# MIMXRT1064 register map
Vendor: nxp.com; File version: 1.0
CPU: CM7 r0p1, little endian, MPU, FPU, VTOR, 4 interrupt priority bits
Registers are 32-bit, read-write, reset 0x0 unless marked. A register's access mark holds for its fields unless they carry their own. Offsets are from the block's base; [hi:lo] are bit positions; {n}, {i} and the like mark numbered series; 'fields as' and 'values as' point back to an identical list.

## DCP — DCP register reference index
Base 0x402FC000; register names take the prefix DCP_
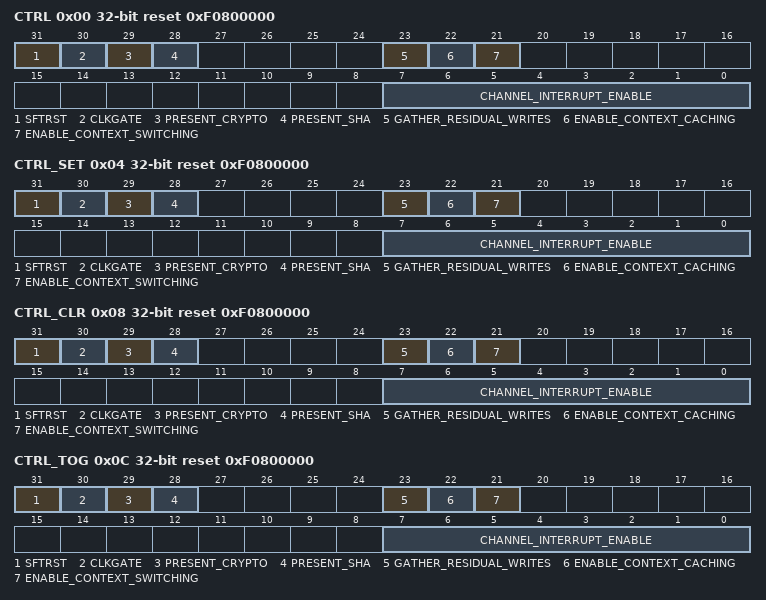
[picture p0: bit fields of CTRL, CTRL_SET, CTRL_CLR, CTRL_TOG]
0x00 CTRL reset 0xF0800000 — DCP control register 0
  [31] SFTRST — Set this bit to zero to enable a normal DCP operation
  [30] CLKGATE — This bit must be set to zero for a normal operation
  [29] PRESENT_CRYPTO ro — Indicates whether the crypto (cipher/hash) functions are present.
    0=Absent; 1=Present
  [28] PRESENT_SHA ro — Indicates whether the SHA1/SHA2 functions are present.
    0=Absent; 1=Present
  [23] GATHER_RESIDUAL_WRITES — The software must set this bit to enable the ragged writes to the unaligned buffers to be gathered between multiple write operations
  [22] ENABLE_CONTEXT_CACHING — The software must set this bit to enable the caching of contexts between the operations
  [21] ENABLE_CONTEXT_SWITCHING — Enable automatic context switching for the channels
  [7:0] CHANNEL_INTERRUPT_ENABLE — Per-channel interrupt enable bit
    1=CH0; 2=CH1; 4=CH2; 8=CH3
0x04 CTRL_SET reset 0xF0800000 — DCP control register 0
  fields as CTRL
0x08 CTRL_CLR reset 0xF0800000 — DCP control register 0
  fields as CTRL
0x0C CTRL_TOG reset 0xF0800000 — DCP control register 0
  fields as CTRL
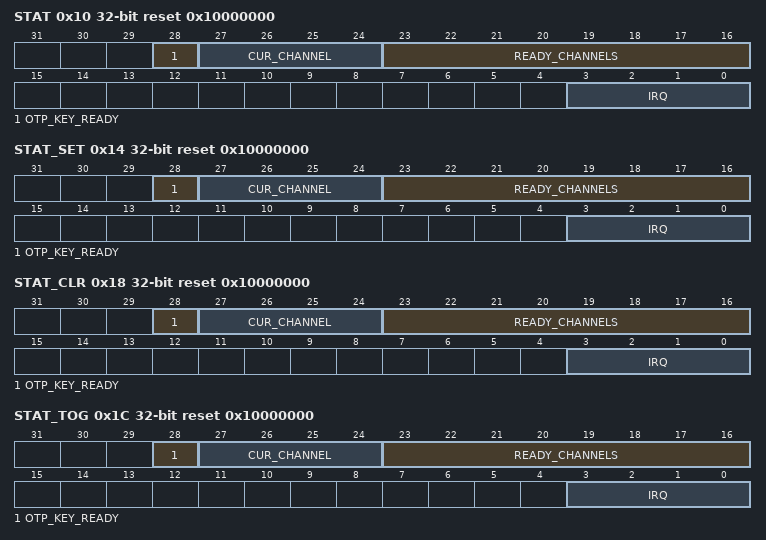
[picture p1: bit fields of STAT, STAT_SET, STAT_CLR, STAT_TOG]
0x10 STAT reset 0x10000000 — DCP status register
  [28] OTP_KEY_READY ro — When set, it indicates that the OTP key is shifted from the fuse block and is ready for use.
  [27:24] CUR_CHANNEL ro — Current (active) channel (encoded)
    0=None; {v}=CH{v-1} (v=1..4)
  [23:16] READY_CHANNELS ro — Indicates which channels are ready to proceed with a transfer (the active channel is also included)
    1=CH0; 2=CH1; 4=CH2; 8=CH3
  [3:0] IRQ — Indicates which channels have pending interrupt requests
0x14 STAT_SET reset 0x10000000 — DCP status register
  fields as STAT
0x18 STAT_CLR reset 0x10000000 — DCP status register
  fields as STAT
0x1C STAT_TOG reset 0x10000000 — DCP status register
  fields as STAT
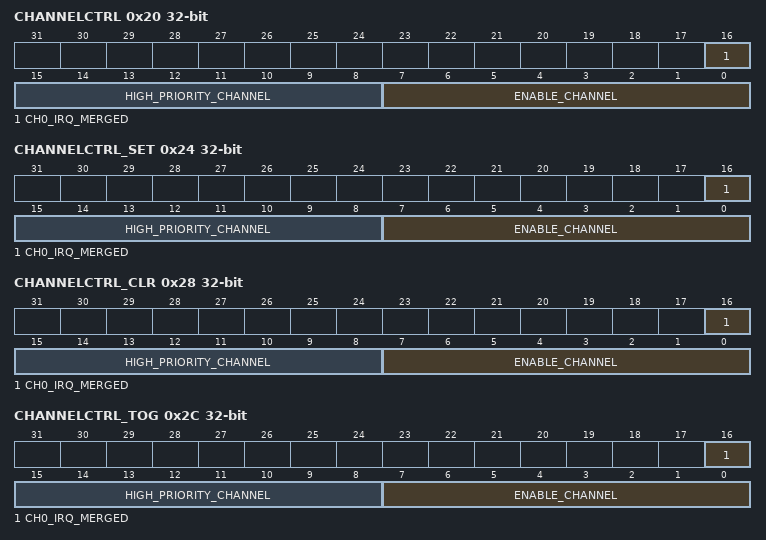
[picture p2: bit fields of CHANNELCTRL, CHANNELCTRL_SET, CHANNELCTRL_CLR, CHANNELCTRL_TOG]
0x20 CHANNELCTRL — DCP channel control register
  [16] CH0_IRQ_MERGED — Indicates that the interrupt for channel 0 must be merged with the other interrupts on the shared dcp_irq interrupt
  [15:8] HIGH_PRIORITY_CHANNEL — Setting a bit in this field causes the corresponding channel to have high-priority arbitration
    1=CH0; 2=CH1; 4=CH2; 8=CH3
  [7:0] ENABLE_CHANNEL — Setting a bit in this field enables the DMA channel associated with it
    1=CH0; 2=CH1; 4=CH2; 8=CH3
0x24 CHANNELCTRL_SET — DCP channel control register
  fields as CHANNELCTRL
0x28 CHANNELCTRL_CLR — DCP channel control register
  fields as CHANNELCTRL
0x2C CHANNELCTRL_TOG — DCP channel control register
  fields as CHANNELCTRL
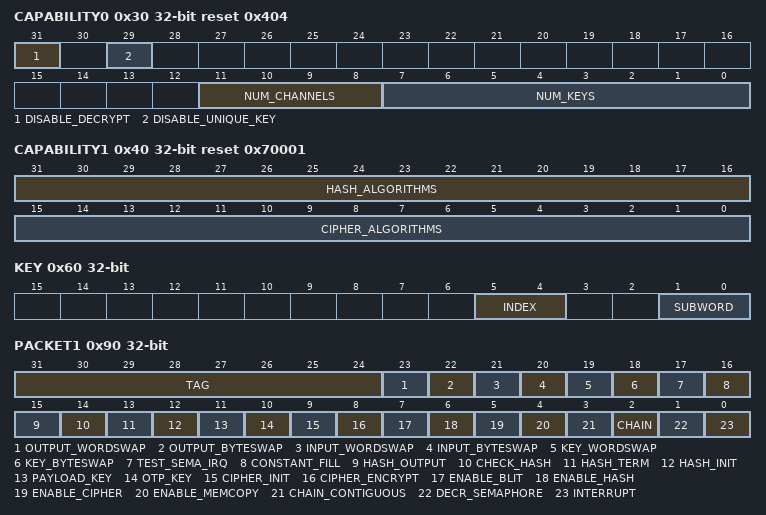
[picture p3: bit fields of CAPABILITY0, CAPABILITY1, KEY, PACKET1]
0x30 CAPABILITY0 reset 0x404 — DCP capability 0 register
  [31] DISABLE_DECRYPT — Write to 1 to disable the decryption
  [29] DISABLE_UNIQUE_KEY — Write to a 1 to disable the per-device unique key
  [11:8] NUM_CHANNELS ro — Encoded value indicating the number of channels implemented in the design
  [7:0] NUM_KEYS ro — Encoded value indicating the number of key-storage locations implemented in the design
0x40 CAPABILITY1 ro reset 0x70001 — DCP capability 1 register
  [31:16] HASH_ALGORITHMS — One-hot field indicating which hashing features are implemented in the hardware
    1=SHA1; 2=CRC32; 4=SHA256
  [15:0] CIPHER_ALGORITHMS — One-hot field indicating which cipher algorithms are available
    1=AES128
0x50 CONTEXT — DCP context buffer pointer
  [31:0] ADDR — Context pointer address
0x60 KEY — DCP key index
  [5:4] INDEX — Key index pointer. The valid indices are 0-[number_keys].
  [1:0] SUBWORD — Key subword pointer
0x70 KEYDATA — DCP key data
  [31:0] DATA — Word 0 data for the key. This is the least-significant word.
0x80 PACKET0 ro — DCP work packet 0 status register
  [31:0] ADDR — Next pointer register
0x90 PACKET1 ro — DCP work packet 1 status register
  [31:24] TAG — Packet Tag
  [23] OUTPUT_WORDSWAP — Reflects whether the DCP engine wordswaps the output data (big-endian data).
  [22] OUTPUT_BYTESWAP — Reflects whether the DCP engine byteswaps the output data (big-endian data).
  [21] INPUT_WORDSWAP — Reflects whether the DCP engine wordswaps the input data (big-endian data).
  [20] INPUT_BYTESWAP — Reflects whether the DCP engine byteswaps the input data (big-endian data).
  [19] KEY_WORDSWAP — Reflects whether the DCP engine swaps the key words (big-endian key).
  [18] KEY_BYTESWAP — Reflects whether the DCP engine swaps the key bytes (big-endian key).
  [17] TEST_SEMA_IRQ — This bit is used to test the channel semaphore transition to 0. FOR TEST USE ONLY!
  [16] CONSTANT_FILL — When this bit is set (MEMCOPY and BLIT modes only), the DCP simply fills the destination buffer with the value found in the source address field
  [15] HASH_OUTPUT — When the hashing is enabled, this bit controls whether the input or output data is hashed.
    0=INPUT; 1=OUTPUT
  [14] CHECK_HASH — Reflects whether the calculated hash value must be compared to the hash provided in the payload.
  [13] HASH_TERM — Reflects whether the current hashing block is the final block in the hashing operation, so the hash padding must be applied by the hardware
  [12] HASH_INIT — Reflects whether the current hashing block is the initial block in the hashing operation, so the hash registers must be initialized before the operation
  [11] PAYLOAD_KEY — When set, it indicates the payload contains the key
  [10] OTP_KEY — Reflects whether a hardware-based key must be used
  [9] CIPHER_INIT — Reflects whether the cipher block must load the initialization vector from the payload for this operation
  [8] CIPHER_ENCRYPT — When the cipher block is enabled, this bit indicates whether the operation is encryption or decryption
    0=DECRYPT; 1=ENCRYPT
  [7] ENABLE_BLIT — Reflects whether the DCP must perform a blit operation
  [6] ENABLE_HASH — Reflects whether the selected hashing function must be enabled for this operation.
  [5] ENABLE_CIPHER — Reflects whether the selected cipher function must be enabled for this operation.
  [4] ENABLE_MEMCOPY — Reflects whether the selected memory-copy (memcopy) function should be enabled for this operation.
  [3] CHAIN_CONTIGUOUS — Reflects whether the next packet's address is located following this packet's payload.
  [2] CHAIN — Reflects whether the next command pointer register must be loaded into the channel's current descriptor pointer
  [1] DECR_SEMAPHORE — Reflects whether the channel's semaphore must be decremented at the end of the current operation
  [0] INTERRUPT — Reflects whether the channel must issue an interrupt upon the completion of the packet.
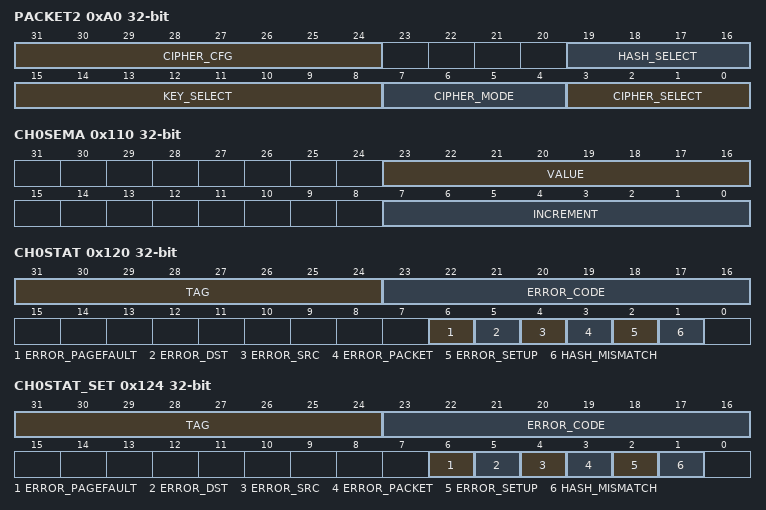
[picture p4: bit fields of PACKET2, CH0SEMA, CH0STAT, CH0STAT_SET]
0xA0 PACKET2 ro — DCP work packet 2 status register
  [31:24] CIPHER_CFG — Cipher configuration bits. Optional configuration bits are required for the ciphers.
  [19:16] HASH_SELECT — Hash Selection Field
    0=SHA1; 1=CRC32; 2=SHA256
  [15:8] KEY_SELECT — Key selection field
    {v}=KEY{v} (v=0..3); 254=UNIQUE_KEY; 255=OTP_KEY
  [7:4] CIPHER_MODE — Cipher mode selection field. Reflects the mode of operation for the cipher operations.
    0=ECB; 1=CBC
  [3:0] CIPHER_SELECT — Cipher selection field
    0=AES128
0xB0 PACKET3 ro — DCP work packet 3 status register
  [31:0] ADDR — Source buffer address pointer
0xC0 PACKET4 ro — DCP work packet 4 status register
  [31:0] ADDR — Destination buffer address pointer
0xD0 PACKET5 ro — DCP work packet 5 status register
  [31:0] COUNT — Byte count register. This value is the working value and updates as the operation proceeds.
0xE0 PACKET6 ro — DCP work packet 6 status register
  [31:0] ADDR — This regiser reflects the payload pointer for the current control packet.
{0x100+0x40*i} CH{i}CMDPTR (i=0..3) — DCP channel {i} command pointer address register
  [31:0] ADDR — Pointer to the descriptor structure to be processed for channel {i}.
0x110 CH0SEMA — DCP channel 0 semaphore register
  [23:16] VALUE ro — This read-only field shows the current (instantaneous) value of the semaphore counter.
  [7:0] INCREMENT — The value written to this field is added to the semaphore count in an atomic way such that the simultaneous software adds and DCP hardware substracts happening on the same clock are protected
0x120 CH0STAT — DCP channel 0 status register
  [31:24] TAG ro — Indicates the tag from the last completed packet in the command structure
  [23:16] ERROR_CODE — Indicates the additional error codes for some of the error conditions
    1=NEXT_CHAIN_IS_0 (Error signalled because the next pointer is 0x00000000); 2=NO_CHAIN (Error signalled because the semaphore is non-zero and neither chain bit is set); 3=CONTEXT_ERROR (Error signalled because an error is reported reading/writing the context buffer); 4=PAYLOAD_ERROR (Error signalled because an error is reported reading/writing the payload); 5=INVALID_MODE (Error signalled because the control packet specifies an invalid mode select (for instance, blit + hash))
  [6] ERROR_PAGEFAULT — This bit indicates that a page fault occurred while converting a virtual address to a physical address
  [5] ERROR_DST — This bit indicates that a bus error occurred when storing to the destination buffer
  [4] ERROR_SRC — This bit indicates that a bus error occurred when reading from the source buffer
  [3] ERROR_PACKET — This bit indicates that a bus error occurred when reading the packet or payload, or when writing the status back to the packet payload
  [2] ERROR_SETUP — This bit indicates that the hardware detected an invalid programming configuration (such as a buffer length that is not a multiple of the natural data size for the operation)
  [1] HASH_MISMATCH — This bit indicates that a hashing check operation mismatched for the control packets that enable the HASH_CHECK bit
0x124 CH0STAT_SET — DCP channel 0 status register
  fields as CH0STAT
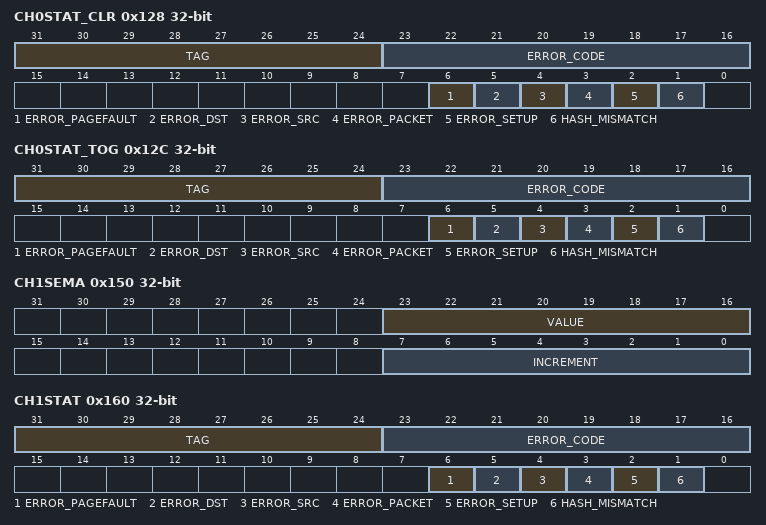
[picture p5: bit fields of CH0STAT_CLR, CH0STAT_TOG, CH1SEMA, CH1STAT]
0x128 CH0STAT_CLR — DCP channel 0 status register
  fields as CH0STAT
0x12C CH0STAT_TOG — DCP channel 0 status register
  fields as CH0STAT
{0x130+0x40*i} CH{i}OPTS (i=0..3) — DCP channel {i} options register
  [15:0] RECOVERY_TIMER — This field indicates the recovery time for the channel
{0x134+0x40*i} CH{i}OPTS_SET (i=0..3) — DCP channel {i} options register
  fields as CH0OPTS
{0x138+0x40*i} CH{i}OPTS_CLR (i=0..3) — DCP channel {i} options register
  fields as CH0OPTS
{0x13C+0x40*i} CH{i}OPTS_TOG (i=0..3) — DCP channel {i} options register
  fields as CH0OPTS
0x150 CH1SEMA — DCP channel 1 semaphore register
  [23:16] VALUE ro — This read-only field shows the current (instantaneous) value of the semaphore counter.
  [7:0] INCREMENT — The value written to this field is added to the semaphore count in an atomic way, such that the simultaneous software adds and the DCP hardware substracts happening on the same clock are protected
0x160 CH1STAT — DCP channel 1 status register
  [31:24] TAG ro — Indicates the tag from the last completed packet in the command structure.
  [23:16] ERROR_CODE — Indicates the additional error codes for some of the error conditions.
    1=NEXT_CHAIN_IS_0 (Error is signalled because the next pointer is 0x00000000.); 2=NO_CHAIN (Error is signalled because the semaphore is of a non-zero value and neither of the chain bits is set.); 3=CONTEXT_ERROR (Error is signalled because an error was reported when reading/writing the context buffer.); 4=PAYLOAD_ERROR (Error is signalled because an error was reported when reading/writing the payload.); 5=INVALID_MODE (Error is signalled because the control packet specifies an invalid mode select (for example, blit + hash).)
  [6] ERROR_PAGEFAULT — This bit indicates that a page fault occurred while converting a virtual address to a physical address
  [5] ERROR_DST — This bit indicates that a bus error occurred when storing to the destination buffer
  [4] ERROR_SRC — This bit indicates that a bus error occurred when reading from the source buffer
  [3] ERROR_PACKET — This bit indicates that a bus error occurred when reading the packet or payload, or when writing the status back to the packet paylaod
  [2] ERROR_SETUP — This bit indicates that the hardware detected an invalid programming configuration (such as a buffer length that is not a multiple of the natural data size for the operation)
  [1] HASH_MISMATCH — This bit indicates that a hashing check operation is mismatched for the control packets that enable the HASH_CHECK bit
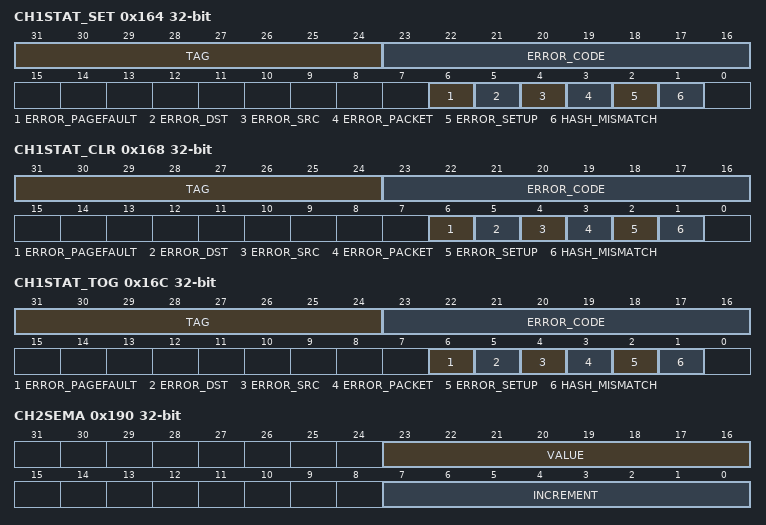
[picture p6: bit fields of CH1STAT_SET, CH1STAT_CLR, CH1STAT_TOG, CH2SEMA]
0x164 CH1STAT_SET — DCP channel 1 status register
  fields as CH1STAT
0x168 CH1STAT_CLR — DCP channel 1 status register
  fields as CH1STAT
0x16C CH1STAT_TOG — DCP channel 1 status register
  fields as CH1STAT
0x190 CH2SEMA — DCP channel 2 semaphore register
  [23:16] VALUE ro — This read-only field shows the current (instantaneous) value of the semaphore counter.
  [7:0] INCREMENT — The value written to this field is added to the semaphore count in an atomic way, such that the simultaneous software adds and DCP hardware substracts happening on the same clock are protected
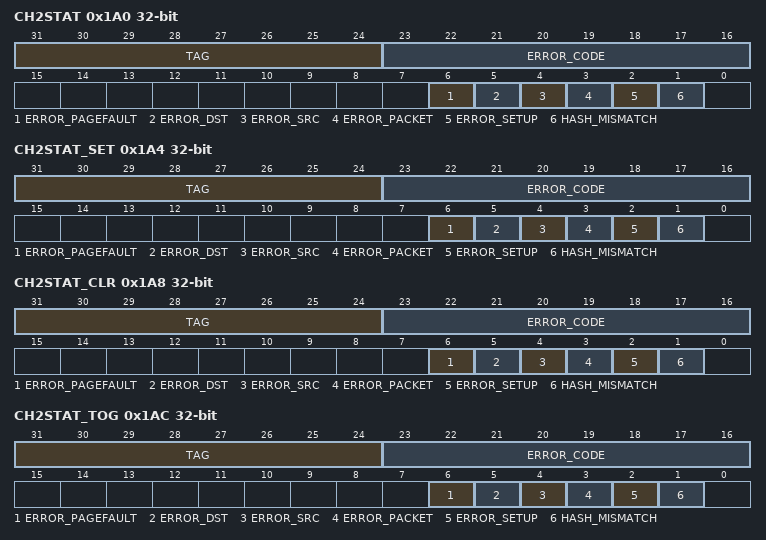
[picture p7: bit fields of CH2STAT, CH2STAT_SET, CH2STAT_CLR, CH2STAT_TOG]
0x1A0 CH2STAT — DCP channel 2 status register
  [31:24] TAG ro — Indicates the tag from the last completed packet in the command structure.
  [23:16] ERROR_CODE — Indicates additional error codes for some of the error conditions.
    1=NEXT_CHAIN_IS_0 (Error is signalled because the next pointer is 0x00000000.); 2=NO_CHAIN (Error is signalled because the semaphore is of a non-zero value and neither of the chain bits is set.); 3=CONTEXT_ERROR (Error is signalled because an error was reported while reading/writing the context buffer.); 4=PAYLOAD_ERROR (Error is signalled because an error was reported while reading/writing the payload.); 5=INVALID_MODE (Error is signalled because the control packet specifies an invalid mode select (for instance, blit + hash).)
  [6] ERROR_PAGEFAULT — This bit indicates that a page fault occurred while converting a virtual address to a physical address
  [5] ERROR_DST — This bit indicates that a bus error occurred when storing to the destination buffer
  [4] ERROR_SRC — This bit indicates that a bus error occurred when reading from the source buffer
  [3] ERROR_PACKET — This bit indicates that a bus error occurred when reading the packet or payload, or when writing the status back to the packet paylaod
  [2] ERROR_SETUP — This bit indicates that the hardware detected an invalid programming configuration (such as a buffer length that is not a multiple of the natural data size for the operation)
  [1] HASH_MISMATCH — This bit indicates that a hashing check operation is mismatched for the control packets that enable the HASH_CHECK bit
0x1A4 CH2STAT_SET — DCP channel 2 status register
  fields as CH2STAT
0x1A8 CH2STAT_CLR — DCP channel 2 status register
  fields as CH2STAT
0x1AC CH2STAT_TOG — DCP channel 2 status register
  fields as CH2STAT
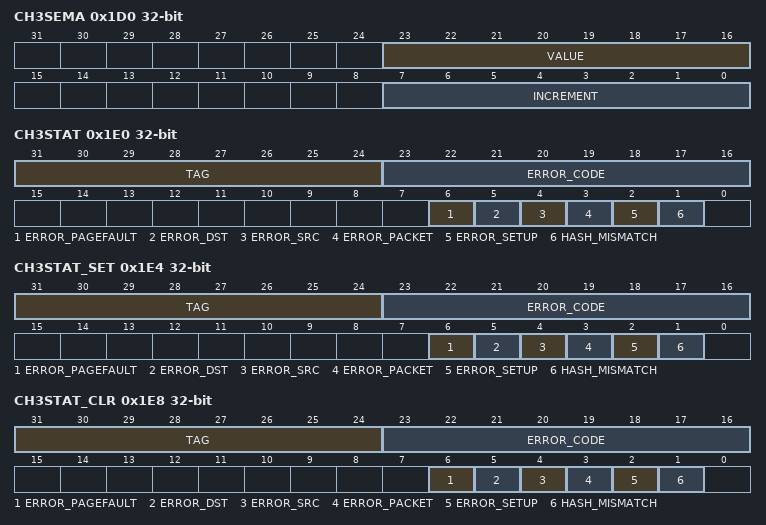
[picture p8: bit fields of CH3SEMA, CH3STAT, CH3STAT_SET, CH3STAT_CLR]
0x1D0 CH3SEMA — DCP channel 3 semaphore register
  fields as CH2SEMA
0x1E0 CH3STAT — DCP channel 3 status register
  [31:24] TAG ro — Indicates the tag from the last completed packet in the command structure.
  [23:16] ERROR_CODE — Indicates additional error codes for some of the error conditions.
    1=NEXT_CHAIN_IS_0 (Error is signalled because the next pointer is 0x00000000.); 2=NO_CHAIN (Error is signalled because the semaphore is of a non-zero value and neither of the chain bits is set.); 3=CONTEXT_ERROR (Error is signalled because an error was reported while reading/writing the context buffer.); 4=PAYLOAD_ERROR (Error is signalled because an error was reported while reading/writing the payload.); 5=INVALID_MODE (Error is signalled because the control packet specifies an invalid mode select (for example, blit + hash).)
  [6] ERROR_PAGEFAULT — This bit indicates that a page fault occurred while converting a virtual address to a physical address
  [5] ERROR_DST — This bit indicates that a bus error occurred when storing to the destination buffer
  [4] ERROR_SRC — This bit indicates that a bus error occurred when reading from the source buffer
  [3] ERROR_PACKET — This bit indicates that a bus error occurred when reading the packet or payload or when writing the status back to the packet paylaod
  [2] ERROR_SETUP — This bit indicates that the hardware detected an invalid programming configuration (such as a buffer length that is not a multiple of the natural data size for the operation)
  [1] HASH_MISMATCH — This bit indicates that a hashing check operation is mismatched for the control packets that enable the HASH_CHECK bit
0x1E4 CH3STAT_SET — DCP channel 3 status register
  fields as CH3STAT
0x1E8 CH3STAT_CLR — DCP channel 3 status register
  fields as CH3STAT
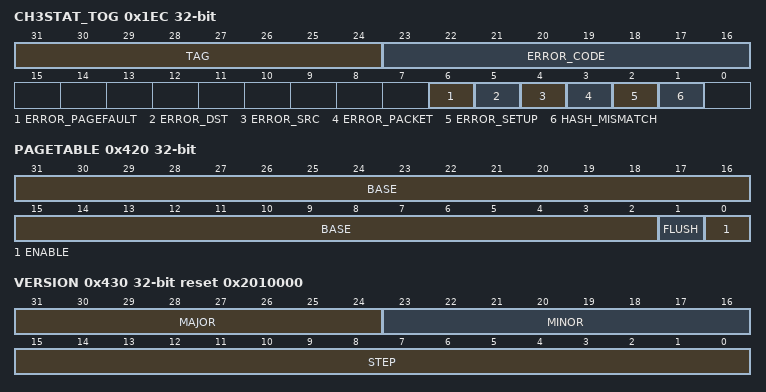
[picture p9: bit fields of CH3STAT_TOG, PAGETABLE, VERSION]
0x1EC CH3STAT_TOG — DCP channel 3 status register
  fields as CH3STAT
0x400 DBGSELECT — DCP debug select register
  [7:0] INDEX — Selects a value to read via the debug data register.
    1=CONTROL; {v}=OTPKEY{v-16} (v=16..19)
0x410 DBGDATA ro — DCP debug data register
  [31:0] DATA — Debug data
0x420 PAGETABLE — DCP page table register
  [31:2] BASE — Page table base address
  [1] FLUSH — Page table flush control. To flush the TLB, write this bit to 1 and then back to 0.
  [0] ENABLE — Page table enable control
0x430 VERSION ro reset 0x2010000 — DCP version register
  [31:24] MAJOR — Fixed read-only value reflecting the MAJOR version of the design implementation.
  [23:16] MINOR — Fixed read-only value reflecting the MINOR version of the design implementation.
  [15:0] STEP — Fixed read-only value reflecting the stepping of the version of the design implementation.
